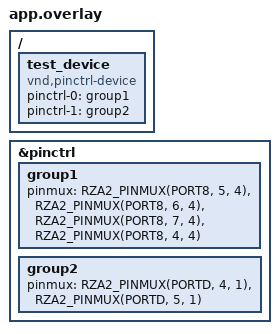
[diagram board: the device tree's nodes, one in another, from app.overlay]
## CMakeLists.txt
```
# Copyright (c) 2023 EPAM Systems
# SPDX-License-Identifier: Apache-2.0

cmake_minimum_required(VERSION 3.20.0)
find_package(Zephyr REQUIRED HINTS $ENV{ZEPHYR_BASE})

project(pinctrl_nrf)

target_sources(app PRIVATE src/main.c ../common/test_device.c)
```

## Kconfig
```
# Copyright (c) 2023 EPAM Systems
# SPDX-License-Identifier: Apache-2.0

mainmenu "pinctrl RZ/A2M DT Test"

source "Kconfig.zephyr"

config PINCTRL_TEST_NON_STATIC
	bool "Access to pin control configuration"
	select PINCTRL_NON_STATIC
	help
	  This option should be selected by unit tests that need to access the pin
	  control configuration defined in a device driver.
```

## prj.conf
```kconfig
CONFIG_ZTEST=y
CONFIG_ZTEST_NEW_API=y
CONFIG_PINCTRL_TEST_NON_STATIC=y
CONFIG_PINCTRL=y
```

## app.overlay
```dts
/*
 * Copyright (c) 2023 EPAM Systems
 * SPDX-License-Identifier: Apache-2.0
 */

/ {
	test_device: test_device {
		compatible = "vnd,pinctrl-device";
		pinctrl-0 = <&group1>;
		pinctrl-1 = <&group2>;
		pinctrl-names = "default", "sleep";
	};
};

&pinctrl {
		/* Note: the groups are just meant for testing if properties and
		   pins are parsed correctly, but do not necessarily represent a
		   feasible combination */
		group1: group1 {
			pinmux = <RZA2_PINMUX(PORT8, 5, 4)>,
				 <RZA2_PINMUX(PORT8, 6, 4)>,
				 <RZA2_PINMUX(PORT8, 7, 4)>,
				 <RZA2_PINMUX(PORT8, 4, 4)>;
		};
		group2: group2 {
			pinmux = <RZA2_PINMUX(PORTD, 4, 1)>,
				 <RZA2_PINMUX(PORTD, 5, 1)>;
		};
};
```

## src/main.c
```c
/*
 * Copyright (c) 2023 EPAM Systems
 *
 * SPDX-License-Identifier: Apache-2.0
 */

#include <zephyr/drivers/pinctrl.h>
#include <zephyr/ztest.h>

#define PINCTRL_STATE_TEST 2

/* pin configuration for test device */
#define TEST_DEVICE DT_NODELABEL(test_device)
PINCTRL_DT_DEV_CONFIG_DECLARE(TEST_DEVICE);
static const struct pinctrl_dev_config *pcfg = PINCTRL_DT_DEV_CONFIG_GET(TEST_DEVICE);

ZTEST(p_rza2_suite, test_dt_extract)
{
	const struct pinctrl_state *scfg;

	zassert_equal(pcfg->state_cnt, 1U);

	scfg = &pcfg->states[0];
	zassert_equal(scfg->id, PINCTRL_STATE_DEFAULT);
}

/**
 * @brief Test that pinctrl_lookup_state() works as expected
 */
ZTEST(p_rza2_suite, test_lookup_state)
{
	int ret;
	const struct pinctrl_state *scfg;

	ret = pinctrl_lookup_state(pcfg, PINCTRL_STATE_DEFAULT, &scfg);
	zassert_equal(ret, 0);
	zassert_equal_ptr(scfg, &pcfg->states[0], NULL);

	/* There shouldn't be sleep state. It is ignored in power management is disabled */
	ret = pinctrl_lookup_state(pcfg, PINCTRL_STATE_TEST, &scfg);
	zassert_equal(ret, -ENOENT);
}

/**
 * @brief Test that pinctrl_apply_state() works as expected.
 */
ZTEST(p_rza2_suite, test_apply_state)
{
	zassert_ok(pinctrl_apply_state(pcfg, PINCTRL_STATE_DEFAULT));
}

ZTEST_SUITE(p_rza2_suite, NULL, NULL, NULL, NULL, NULL);
```
